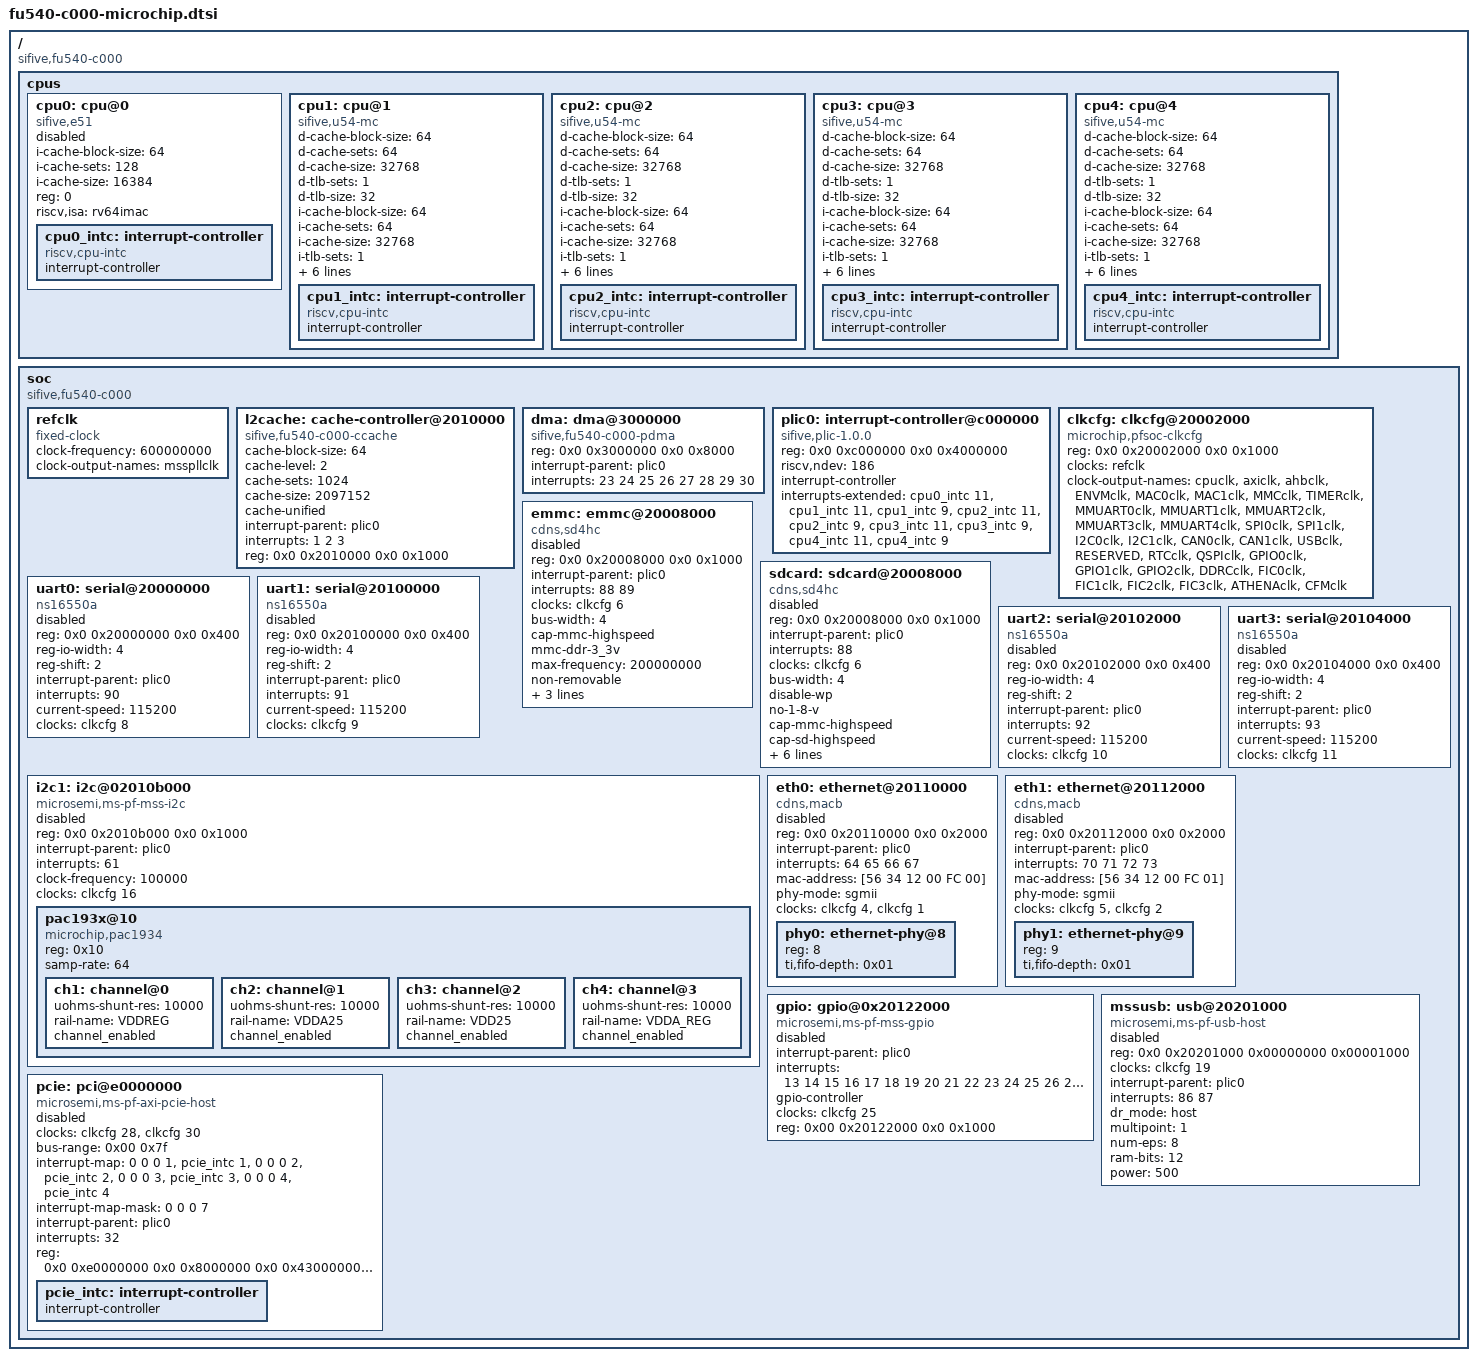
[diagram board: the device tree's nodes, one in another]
// SPDX-License-Identifier: (GPL-2.0 OR MIT)
/* Copyright (c) 2018-2019 SiFive, Inc */
/* Copyright (c) 2020 Foundries.io */

/dts-v1/;

/ {
	#address-cells = <2>;
	#size-cells = <2>;
	compatible = "sifive,fu540-c000", "sifive,fu540";

	cpus {
		#address-cells = <1>;
		#size-cells = <0>;
		cpu0: cpu@0 {
			compatible = "sifive,e51", "sifive,rocket0", "riscv";
			device_type = "cpu";
			i-cache-block-size = <64>;
			i-cache-sets = <128>;
			i-cache-size = <16384>;
			reg = <0>;
			riscv,isa = "rv64imac";
			status = "disabled";
			cpu0_intc: interrupt-controller {
				#interrupt-cells = <1>;
				compatible = "riscv,cpu-intc";
				interrupt-controller;
			};
		};
		cpu1: cpu@1 {
			compatible = "sifive,u54-mc", "sifive,rocket0", "riscv";
			d-cache-block-size = <64>;
			d-cache-sets = <64>;
			d-cache-size = <32768>;
			d-tlb-sets = <1>;
			d-tlb-size = <32>;
			device_type = "cpu";
			i-cache-block-size = <64>;
			i-cache-sets = <64>;
			i-cache-size = <32768>;
			i-tlb-sets = <1>;
			i-tlb-size = <32>;
			mmu-type = "riscv,sv39";
			reg = <1>;
			riscv,isa = "rv64imafdc";
			tlb-split;
			next-level-cache = <&l2cache>;
			cpu1_intc: interrupt-controller {
				#interrupt-cells = <1>;
				compatible = "riscv,cpu-intc";
				interrupt-controller;
			};
		};
		cpu2: cpu@2 {
			compatible = "sifive,u54-mc", "sifive,rocket0", "riscv";
			d-cache-block-size = <64>;
			d-cache-sets = <64>;
			d-cache-size = <32768>;
			d-tlb-sets = <1>;
			d-tlb-size = <32>;
			device_type = "cpu";
			i-cache-block-size = <64>;
			i-cache-sets = <64>;
			i-cache-size = <32768>;
			i-tlb-sets = <1>;
			i-tlb-size = <32>;
			mmu-type = "riscv,sv39";
			reg = <2>;
			riscv,isa = "rv64imafdc";
			tlb-split;
			next-level-cache = <&l2cache>;
			cpu2_intc: interrupt-controller {
				#interrupt-cells = <1>;
				compatible = "riscv,cpu-intc";
				interrupt-controller;
			};
		};
		cpu3: cpu@3 {
			compatible = "sifive,u54-mc", "sifive,rocket0", "riscv";
			d-cache-block-size = <64>;
			d-cache-sets = <64>;
			d-cache-size = <32768>;
			d-tlb-sets = <1>;
			d-tlb-size = <32>;
			device_type = "cpu";
			i-cache-block-size = <64>;
			i-cache-sets = <64>;
			i-cache-size = <32768>;
			i-tlb-sets = <1>;
			i-tlb-size = <32>;
			mmu-type = "riscv,sv39";
			reg = <3>;
			riscv,isa = "rv64imafdc";
			tlb-split;
			next-level-cache = <&l2cache>;
			cpu3_intc: interrupt-controller {
				#interrupt-cells = <1>;
				compatible = "riscv,cpu-intc";
				interrupt-controller;
			};
		};
		cpu4: cpu@4 {
			compatible = "sifive,u54-mc", "sifive,rocket0", "riscv";
			d-cache-block-size = <64>;
			d-cache-sets = <64>;
			d-cache-size = <32768>;
			d-tlb-sets = <1>;
			d-tlb-size = <32>;
			device_type = "cpu";
			i-cache-block-size = <64>;
			i-cache-sets = <64>;
			i-cache-size = <32768>;
			i-tlb-sets = <1>;
			i-tlb-size = <32>;
			mmu-type = "riscv,sv39";
			reg = <4>;
			riscv,isa = "rv64imafdc";
			tlb-split;
			next-level-cache = <&l2cache>;
			cpu4_intc: interrupt-controller {
				#interrupt-cells = <1>;
				compatible = "riscv,cpu-intc";
				interrupt-controller;
			};
		};
	};
	soc {
		#address-cells = <2>;
		#size-cells = <2>;
		compatible = "sifive,fu540-c000", "sifive,fu540", "simple-bus";
		ranges;
		refclk: refclk {
			#clock-cells = <0>;
			compatible = "fixed-clock";
			clock-frequency = <600000000>;
			clock-output-names = "msspllclk";
		};
		l2cache: cache-controller@2010000 {
			compatible = "sifive,fu540-c000-ccache", "cache";
			cache-block-size = <64>;
			cache-level = <2>;
			cache-sets = <1024>;
			cache-size = <2097152>;
			cache-unified;
			interrupt-parent = <&plic0>;
			interrupts = <1 2 3>;
			reg = <0x0 0x2010000 0x0 0x1000>;
		};
		dma: dma@3000000 {
			compatible = "sifive,fu540-c000-pdma";
			reg = <0x0 0x3000000 0x0 0x8000>;
			interrupt-parent = <&plic0>;
			interrupts = <23 24 25 26 27 28 29 30>;
			#dma-cells = <1>;
		};
		plic0: interrupt-controller@c000000 {
			#interrupt-cells = <1>;
			compatible = "sifive,plic-1.0.0";
			reg = <0x0 0xc000000 0x0 0x4000000>;
			riscv,ndev = <186>;
			interrupt-controller;
			interrupts-extended = <
				&cpu0_intc 11
				&cpu1_intc 11 &cpu1_intc 9
				&cpu2_intc 11 &cpu2_intc 9
				&cpu3_intc 11 &cpu3_intc 9
				&cpu4_intc 11 &cpu4_intc 9>;
		};
		clkcfg: clkcfg@20002000 {
			#clock-cells = <1>;
			compatible = "microchip,pfsoc-clkcfg";
			reg = <0x0 0x20002000 0x0 0x1000>;
			reg-names = "mss_sysreg";
			clocks = <&refclk>;
			clock-output-names = "cpuclk", "axiclk", "ahbclk",
				"ENVMclk", "MAC0clk", "MAC1clk", "MMCclk",
				"TIMERclk", "MMUART0clk", "MMUART1clk",
				"MMUART2clk", "MMUART3clk", "MMUART4clk",
				"SPI0clk", "SPI1clk", "I2C0clk", "I2C1clk",
				"CAN0clk", "CAN1clk", "USBclk", "RESERVED",
				"RTCclk", "QSPIclk", "GPIO0clk", "GPIO1clk",
				"GPIO2clk", "DDRCclk", "FIC0clk", "FIC1clk",
				"FIC2clk", "FIC3clk", "ATHENAclk", "CFMclk";
		};
		emmc: emmc@20008000 {
			compatible = "cdns,sd4hc";
			reg = <0x0 0x20008000 0x0 0x1000>;
			interrupt-parent = <&plic0>;
			interrupts = <88 89>;
			pinctrl-names = "default";
			clocks = <&clkcfg 6>;
			bus-width = <4>;
			cap-mmc-highspeed;
			mmc-ddr-3_3v;
			max-frequency = <200000000>;
			non-removable;
			no-sd;
			no-sdio;
			voltage-ranges = <3300 3300>;
			status = "disabled";
		};
		sdcard: sdcard@20008000 {
			compatible = "cdns,sd4hc";
			reg = <0x0 0x20008000 0x0 0x1000>;
			interrupt-parent = <&plic0>;
			interrupts = <88>;
			pinctrl-names = "default";
			clocks = <&clkcfg 6>;
			bus-width = <4>;
			disable-wp;
			no-1-8-v;
			cap-mmc-highspeed;
			cap-sd-highspeed;
			card-detect-delay = <200>;
			sd-uhs-sdr12;
			sd-uhs-sdr25;
			sd-uhs-sdr50;
			sd-uhs-sdr104;
			max-frequency = <200000000>;
			status = "disabled";
		};
		uart0: serial@20000000 {
			compatible = "ns16550a";
			reg = <0x0 0x20000000 0x0 0x400>;
			reg-io-width = <4>;
			reg-shift = <2>;
			interrupt-parent = <&plic0>;
			interrupts = <90>;
			current-speed = <115200>;
			clocks = <&clkcfg 8>;
			status = "disabled";
		};
		uart1: serial@20100000 {
			compatible = "ns16550a";
			reg = <0x0 0x20100000 0x0 0x400>;
			reg-io-width = <4>;
			reg-shift = <2>;
			interrupt-parent = <&plic0>;
			interrupts = <91>;
			current-speed = <115200>;
			clocks = <&clkcfg 9>;
			status = "disabled";
		};
		uart2: serial@20102000 {
			compatible = "ns16550a";
			reg = <0x0 0x20102000 0x0 0x400>;
			reg-io-width = <4>;
			reg-shift = <2>;
			interrupt-parent = <&plic0>;
			interrupts = <92>;
			current-speed = <115200>;
			clocks = <&clkcfg 10>;
			status = "disabled";
		};
		uart3: serial@20104000 {
			compatible = "ns16550a";
			reg = <0x0 0x20104000 0x0 0x400>;
			reg-io-width = <4>;
			reg-shift = <2>;
			interrupt-parent = <&plic0>;
			interrupts = <93>;
			current-speed = <115200>;
			clocks = <&clkcfg 11>;
			status = "disabled";
		};
		i2c1: i2c@02010b000 {
			#address-cells = <1>;
			#size-cells = <0>;
			compatible = "microsemi,ms-pf-mss-i2c";
			reg = <0x0 0x2010b000 0x0 0x1000>;
			interrupt-parent = <&plic0>;
			interrupts = <61>;
			clock-frequency = <100000>;
			clocks = <&clkcfg 16>;
			status = "disabled";
			pac193x@10 {
				compatible = "microchip,pac1934";
				reg = <0x10>;
				samp-rate = <64>;
				ch1: channel@0 {
					uohms-shunt-res = <10000>;
					rail-name = "VDDREG";
					channel_enabled;
				};
				ch2: channel@1 {
					uohms-shunt-res = <10000>;
					rail-name = "VDDA25";
					channel_enabled;
				};
				ch3: channel@2 {
					uohms-shunt-res = <10000>;
					rail-name = "VDD25";
					channel_enabled;
				};
				ch4: channel@3 {
					uohms-shunt-res = <10000>;
					rail-name = "VDDA_REG";
					channel_enabled;
				};
			};
		};
		eth0: ethernet@20110000 {
			compatible = "cdns,macb";
			reg = <0x0 0x20110000 0x0 0x2000>;
			interrupt-parent = <&plic0>;
			interrupts = <64 65 66 67>;
			mac-address = [56 34 12 00 FC 00];
			phy-mode = "sgmii";
			clocks = <&clkcfg 4>, <&clkcfg 1>;
			clock-names = "pclk", "hclk";
			status = "disabled";
			#address-cells = <1>;
			#size-cells = <0>;
			phy0: ethernet-phy@8 {
				reg = <8>;
				ti,fifo-depth = <0x01>;
			};
		};
		eth1: ethernet@20112000 {
			compatible = "cdns,macb";
			reg = <0x0 0x20112000 0x0 0x2000>;
			interrupt-parent = <&plic0>;
			interrupts = <70 71 72 73>;
			mac-address = [56 34 12 00 FC 01];
			phy-mode = "sgmii";
			clocks = <&clkcfg 5>, <&clkcfg 2>;
			clock-names = "pclk", "hclk";
			status = "disabled";
			#address-cells = <1>;
			#size-cells = <0>;
			phy1: ethernet-phy@9 {
				reg = <9>;
				ti,fifo-depth = <0x01>;
			};
		};
		gpio: gpio@0x20122000 {
			compatible = "microsemi,ms-pf-mss-gpio";
			interrupt-parent = <&plic0>;
			interrupts = <
				13 14 15 16 17 18 19 20 21 22 23 24 25 26
				27 28 29 30 31 32 33 34 35 36 37 38 39 40
				41 42 43 44>;
			gpio-controller;
			clocks = <&clkcfg 25>;
			reg = <0x00 0x20122000 0x0 0x1000>;
			reg-names = "control";
			#gpio-cells = <2>;
			status = "disabled";
		};
		mssusb: usb@20201000 {
			compatible = "microsemi,ms-pf-usb-host";
			reg = <0x0 0x20201000 0x00000000 0x00001000>;
			reg-names = "mc","control";
			clocks = <&clkcfg 19>;
			interrupt-parent = <&plic0>;
			interrupts = <86 87>;
			interrupt-names = "mc","dma";
			dr_mode = "host";
			multipoint = <1>;
			num-eps = <8>;
			ram-bits = <12>;
			power = <500>;
			status = "disabled";
		};
		pcie: pci@e0000000 {
			#address-cells = <3>;
			#interrupt-cells = <1>;
			#size-cells = <2>;
			compatible = "microsemi,ms-pf-axi-pcie-host";
			device_type = "pci";
			clocks = <&clkcfg 28>, <&clkcfg 30>;
			clock-names = "pcie", "regclk";
			bus-range = <0x00 0x7f>;
			interrupt-map = <0 0 0 1 &pcie_intc 1>,
					<0 0 0 2 &pcie_intc 2>,
					<0 0 0 3 &pcie_intc 3>,
					<0 0 0 4 &pcie_intc 4>;
			interrupt-map-mask = <0 0 0 7>;
			interrupt-parent = <&plic0>;
			interrupts = <32>;
			ranges = <0x43000000 0x0 0xe8000000 0x0 0xe8000000 0x0 0x8000000>;
			reg = <0x0 0xe0000000 0x0 0x8000000 0x0 0x43000000 0x0 0x10000>;
			reg-names = "control", "apb";
			status = "disabled";
			pcie_intc: interrupt-controller {
				#address-cells = <0>;
				#interrupt-cells = <1>;
				interrupt-controller;
			};
		};
	};
};
